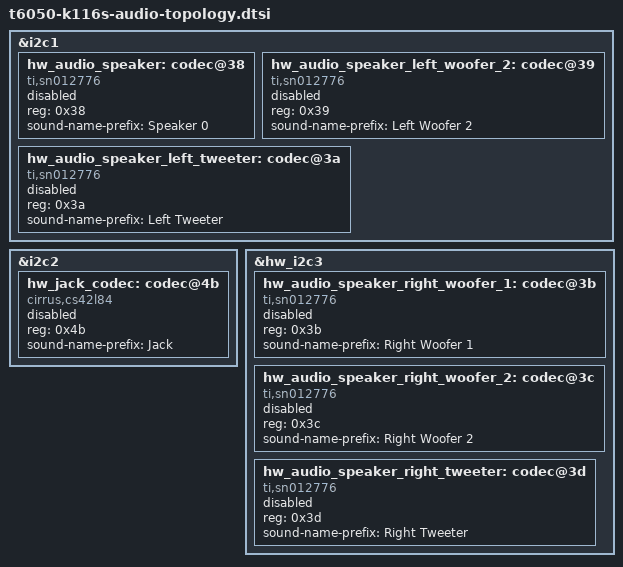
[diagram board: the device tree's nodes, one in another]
// SPDX-License-Identifier: GPL-2.0+ OR MIT
/* Codec identities only; no amplifier programming or acoustic configuration. */

&i2c1 {
	#address-cells = <1>;
	#size-cells = <0>;

	hw_audio_speaker: codec@38 {
		compatible = "ti,sn012776", "ti,tas2764";
		reg = <0x38>;
		#sound-dai-cells = <0>;
		sound-name-prefix = "Speaker 0";
		status = "disabled";
	};

	hw_audio_speaker_left_woofer_2: codec@39 {
		compatible = "ti,sn012776", "ti,tas2764";
		reg = <0x39>;
		#sound-dai-cells = <0>;
		sound-name-prefix = "Left Woofer 2";
		status = "disabled";
	};

	hw_audio_speaker_left_tweeter: codec@3a {
		compatible = "ti,sn012776", "ti,tas2764";
		reg = <0x3a>;
		#sound-dai-cells = <0>;
		sound-name-prefix = "Left Tweeter";
		status = "disabled";
	};
};

&i2c2 {
	#address-cells = <1>;
	#size-cells = <0>;

	hw_jack_codec: codec@4b {
		compatible = "cirrus,cs42l84";
		reg = <0x4b>;
		#sound-dai-cells = <0>;
		sound-name-prefix = "Jack";
		status = "disabled";
	};
};

&hw_i2c3 {
	#address-cells = <1>;
	#size-cells = <0>;

	hw_audio_speaker_right_woofer_1: codec@3b {
		compatible = "ti,sn012776", "ti,tas2764";
		reg = <0x3b>;
		#sound-dai-cells = <0>;
		sound-name-prefix = "Right Woofer 1";
		status = "disabled";
	};

	hw_audio_speaker_right_woofer_2: codec@3c {
		compatible = "ti,sn012776", "ti,tas2764";
		reg = <0x3c>;
		#sound-dai-cells = <0>;
		sound-name-prefix = "Right Woofer 2";
		status = "disabled";
	};

	hw_audio_speaker_right_tweeter: codec@3d {
		compatible = "ti,sn012776", "ti,tas2764";
		reg = <0x3d>;
		#sound-dai-cells = <0>;
		sound-name-prefix = "Right Tweeter";
		status = "disabled";
	};
};
